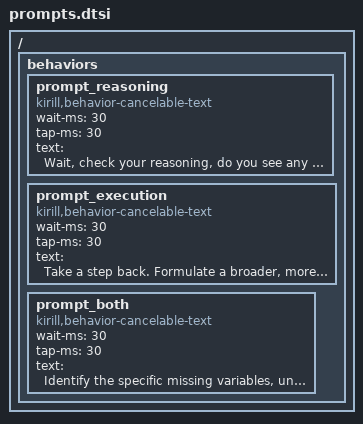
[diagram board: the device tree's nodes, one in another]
/*
 * Host-independent, cancelable prompt behaviors.
 *
 * They type into the focused text field but deliberately do not send Enter.
 * Press any prompt key while one is running to stop it immediately.
 *
 * Exact output:
 *   Reason:   Wait, check your reasoning, do you see any flaws or better alternatives?
 *   Abstract: Take a step back. Formulate a broader, more abstract version of my question that captures the core mechanics of the problem without any of my specific details. Answer that abstract question first, then use that foundational knowledge to solve my specific request
 *   Plan:     Identify the specific missing variables, unstated assumptions, or system constraints required to execute this flawlessly. Ask for my input on them using high-SNR context. Generate 2 to 5 materially distinct execution paths (A, B, C, D, E), ranking them strictly from highest long-term structural value to highest short-term immediate utility. For each path, explicitly define the primary trade-off being made. Finally, declare your definitive recommendation, and state the exact condition or new piece of information that would force you to change this recommendation
 */

/ {
  behaviors {
    prompt_reasoning: prompt_reasoning {
      compatible = "kirill,behavior-cancelable-text";
      #binding-cells = <0>;
      wait-ms = <30>;
      tap-ms = <30>;
      text = "Wait, check your reasoning, do you see any flaws or better alternatives?";
    };

    prompt_execution: prompt_execution {
      compatible = "kirill,behavior-cancelable-text";
      #binding-cells = <0>;
      wait-ms = <30>;
      tap-ms = <30>;
      text = "Take a step back. Formulate a broader, more abstract version of my question that captures the core mechanics of the problem without any of my specific details. Answer that abstract question first, then use that foundational knowledge to solve my specific request";
    };

    prompt_both: prompt_both {
      compatible = "kirill,behavior-cancelable-text";
      #binding-cells = <0>;
      wait-ms = <30>;
      tap-ms = <30>;
      text = "Identify the specific missing variables, unstated assumptions, or system constraints required to execute this flawlessly. Ask for my input on them using high-SNR context. Generate 2 to 5 materially distinct execution paths (A, B, C, D, E), ranking them strictly from highest long-term structural value to highest short-term immediate utility. For each path, explicitly define the primary trade-off being made. Finally, declare your definitive recommendation, and state the exact condition or new piece of information that would force you to change this recommendation";
    };
  };
};
